# STM32L552 register map
File version: 1.0
CPU: CM33 r0p1, little endian, MPU, FPU, 3 interrupt priority bits
Registers are 32-bit, read-write, reset 0x0 unless marked. A register's access mark holds for its fields unless they carry their own. Offsets are from the block's base; [hi:lo] are bit positions; {n}, {i} and the like mark numbered series.

## GTZC_MPCBB1
Base 0x40032C00
Same registers: GTZC_MPCBB2 0x40033000, SEC_GTZC_MPCBB1 0x50032C00, SEC_GTZC_MPCBB2 0x50033000
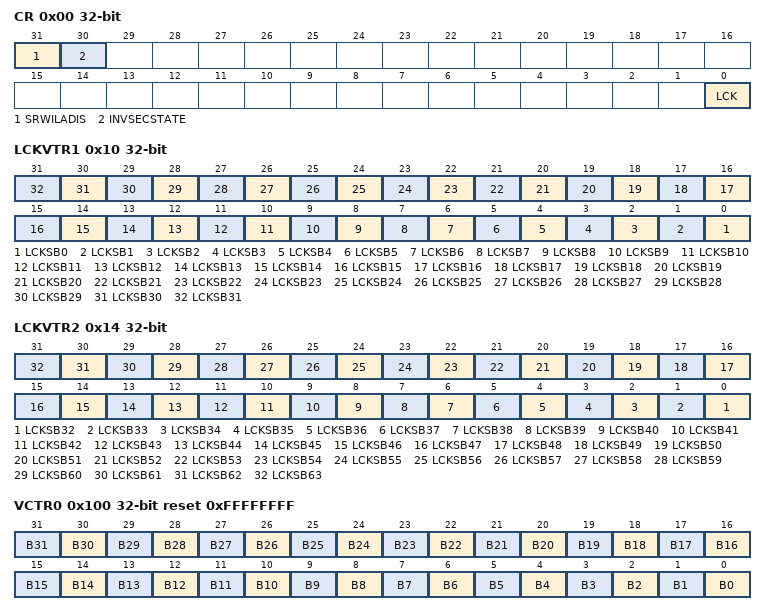
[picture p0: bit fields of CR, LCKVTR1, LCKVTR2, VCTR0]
0x00 CR — MPCBB control register
  [31] SRWILADIS, [30] INVSECSTATE, [0] LCK
0x10 LCKVTR1 — MPCBB control register
  [n] LCKSB{n} (n=0..31)
0x14 LCKVTR2 — MPCBB control register
  [n-32] LCKSB{n} (n=32..63)
0x100 VCTR0 reset 0xFFFFFFFF — MPCBBx vector register
  [n] B{n} (n=0..31)
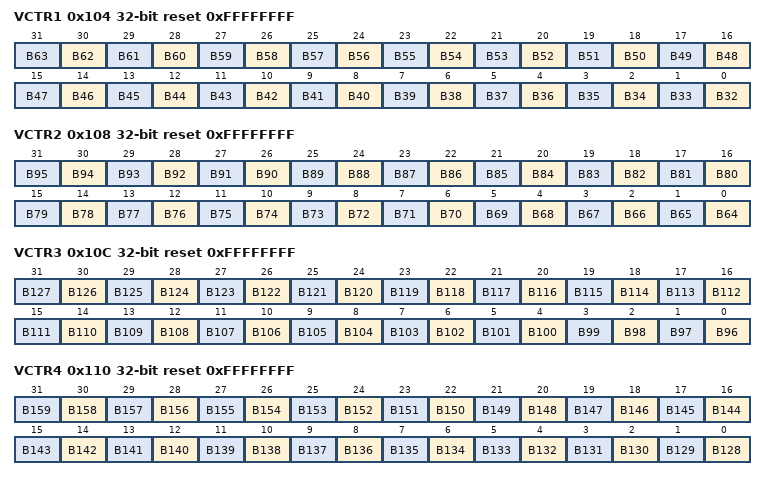
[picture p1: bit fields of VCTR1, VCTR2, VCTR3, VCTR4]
0x104 VCTR1 reset 0xFFFFFFFF — MPCBBx vector register
  [n-32] B{n} (n=32..63)
0x108 VCTR2 reset 0xFFFFFFFF — MPCBBx vector register
  [n-64] B{n} (n=64..95)
0x10C VCTR3 reset 0xFFFFFFFF — MPCBBx vector register
  [n-96] B{n} (n=96..127)
0x110 VCTR4 reset 0xFFFFFFFF — MPCBBx vector register
  [n-128] B{n} (n=128..159)
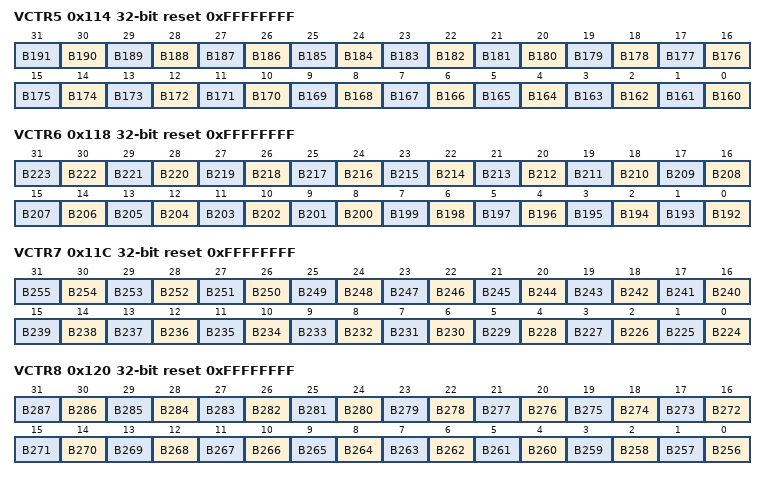
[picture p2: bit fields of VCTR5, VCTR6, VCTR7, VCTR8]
0x114 VCTR5 reset 0xFFFFFFFF — MPCBBx vector register
  [n-160] B{n} (n=160..191)
0x118 VCTR6 reset 0xFFFFFFFF — MPCBBx vector register
  [n-192] B{n} (n=192..223)
0x11C VCTR7 reset 0xFFFFFFFF — MPCBBx vector register
  [n-224] B{n} (n=224..255)
0x120 VCTR8 reset 0xFFFFFFFF — MPCBBx vector register
  [n-256] B{n} (n=256..287)
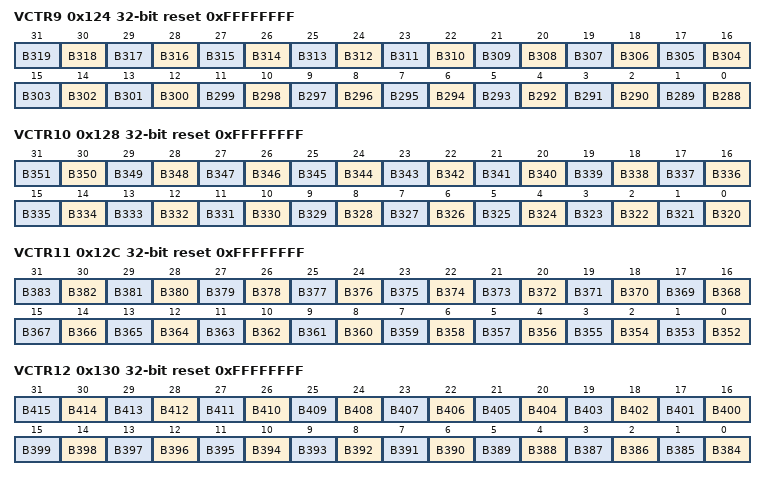
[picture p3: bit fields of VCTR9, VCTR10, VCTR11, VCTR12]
0x124 VCTR9 reset 0xFFFFFFFF — MPCBBx vector register
  [n-288] B{n} (n=288..319)
0x128 VCTR10 reset 0xFFFFFFFF — MPCBBx vector register
  [n-320] B{n} (n=320..351)
0x12C VCTR11 reset 0xFFFFFFFF — MPCBBx vector register
  [n-352] B{n} (n=352..383)
0x130 VCTR12 reset 0xFFFFFFFF — MPCBBx vector register
  [n-384] B{n} (n=384..415)
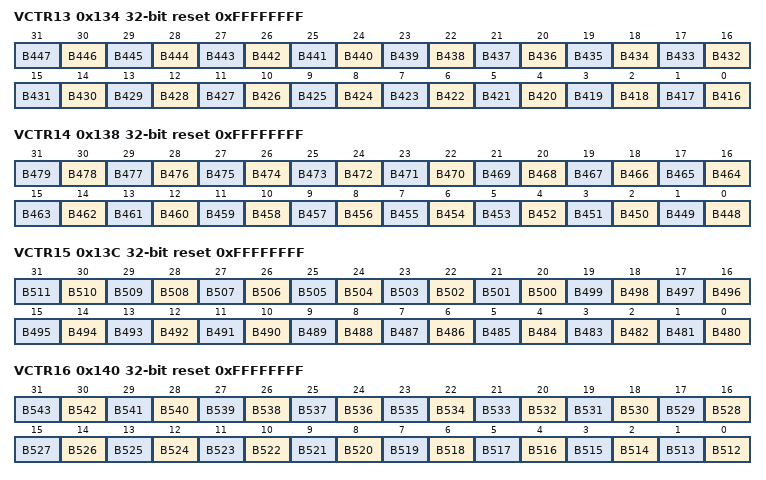
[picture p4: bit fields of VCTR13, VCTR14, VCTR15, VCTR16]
0x134 VCTR13 reset 0xFFFFFFFF — MPCBBx vector register
  [n-416] B{n} (n=416..447)
0x138 VCTR14 reset 0xFFFFFFFF — MPCBBx vector register
  [n-448] B{n} (n=448..479)
0x13C VCTR15 reset 0xFFFFFFFF — MPCBBx vector register
  [n-480] B{n} (n=480..511)
0x140 VCTR16 reset 0xFFFFFFFF — MPCBBx vector register
  [n-512] B{n} (n=512..543)
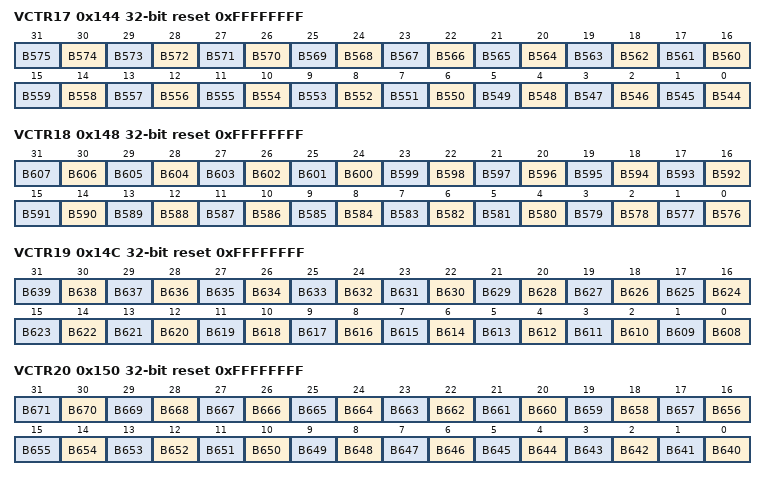
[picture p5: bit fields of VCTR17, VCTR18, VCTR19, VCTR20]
0x144 VCTR17 reset 0xFFFFFFFF — MPCBBx vector register
  [n-544] B{n} (n=544..575)
0x148 VCTR18 reset 0xFFFFFFFF — MPCBBx vector register
  [n-576] B{n} (n=576..607)
0x14C VCTR19 reset 0xFFFFFFFF — MPCBBx vector register
  [n-608] B{n} (n=608..639)
0x150 VCTR20 reset 0xFFFFFFFF — MPCBBx vector register
  [n-640] B{n} (n=640..671)
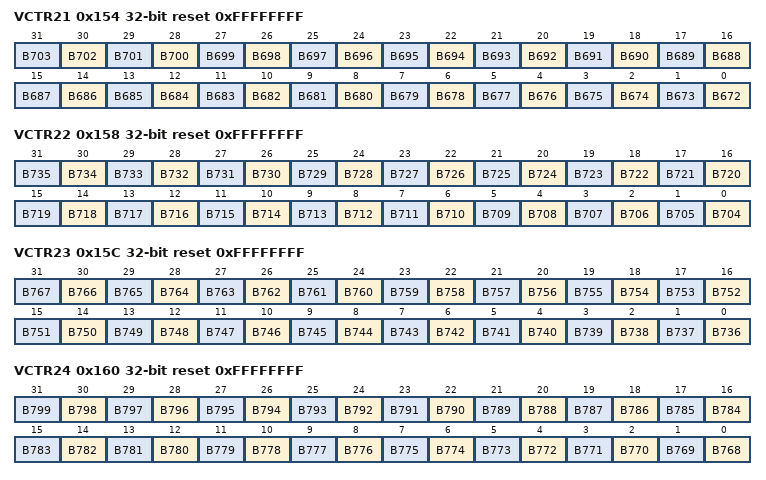
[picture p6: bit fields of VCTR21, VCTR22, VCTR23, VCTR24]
0x154 VCTR21 reset 0xFFFFFFFF — MPCBBx vector register
  [n-672] B{n} (n=672..703)
0x158 VCTR22 reset 0xFFFFFFFF — MPCBBx vector register
  [n-704] B{n} (n=704..735)
0x15C VCTR23 reset 0xFFFFFFFF — MPCBBx vector register
  [n-736] B{n} (n=736..767)
0x160 VCTR24 reset 0xFFFFFFFF — MPCBBx vector register
  [n-768] B{n} (n=768..799)
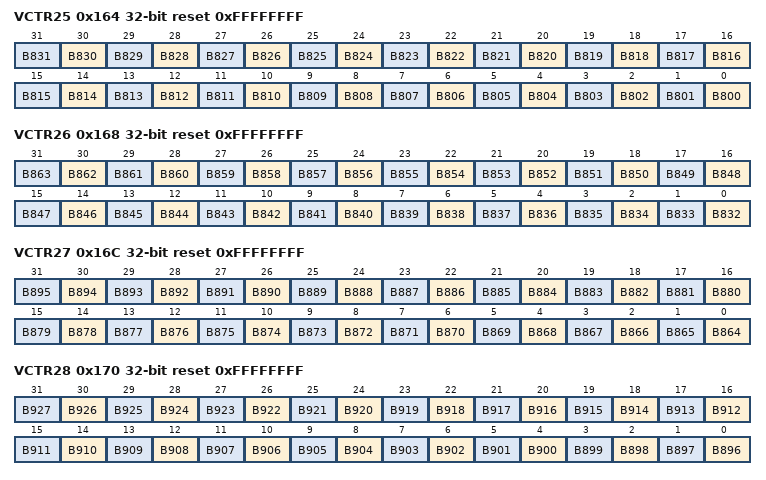
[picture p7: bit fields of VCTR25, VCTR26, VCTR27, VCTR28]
0x164 VCTR25 reset 0xFFFFFFFF — MPCBBx vector register
  [n-800] B{n} (n=800..831)
0x168 VCTR26 reset 0xFFFFFFFF — MPCBBx vector register
  [n-832] B{n} (n=832..863)
0x16C VCTR27 reset 0xFFFFFFFF — MPCBBx vector register
  [n-864] B{n} (n=864..895)
0x170 VCTR28 reset 0xFFFFFFFF — MPCBBx vector register
  [n-896] B{n} (n=896..927)
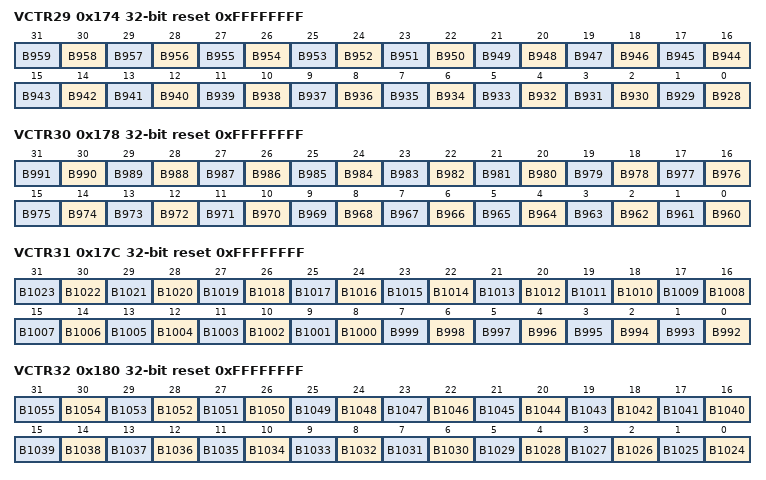
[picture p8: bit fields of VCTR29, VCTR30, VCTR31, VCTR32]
0x174 VCTR29 reset 0xFFFFFFFF — MPCBBx vector register
  [n-928] B{n} (n=928..959)
0x178 VCTR30 reset 0xFFFFFFFF — MPCBBx vector register
  [n-960] B{n} (n=960..991)
0x17C VCTR31 reset 0xFFFFFFFF — MPCBBx vector register
  [n-992] B{n} (n=992..1023)
0x180 VCTR32 reset 0xFFFFFFFF — MPCBBx vector register
  [n-1024] B{n} (n=1024..1055)
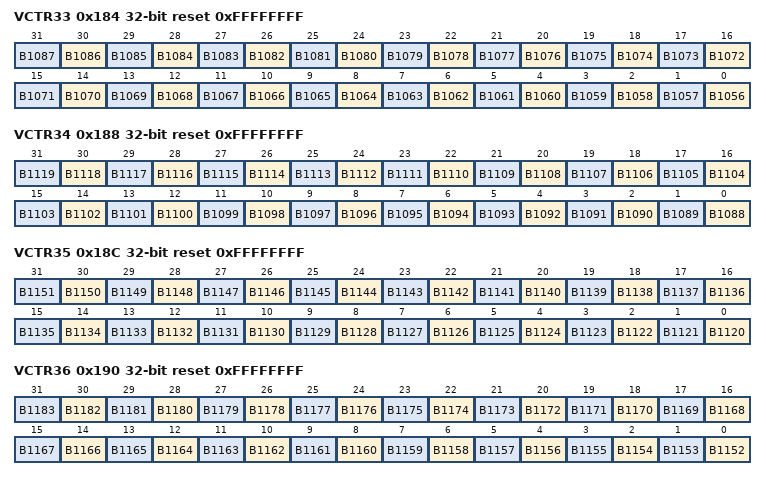
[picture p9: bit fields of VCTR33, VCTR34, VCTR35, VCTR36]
0x184 VCTR33 reset 0xFFFFFFFF — MPCBBx vector register
  [n-1056] B{n} (n=1056..1087)
0x188 VCTR34 reset 0xFFFFFFFF — MPCBBx vector register
  [n-1088] B{n} (n=1088..1119)
0x18C VCTR35 reset 0xFFFFFFFF — MPCBBx vector register
  [n-1120] B{n} (n=1120..1151)
0x190 VCTR36 reset 0xFFFFFFFF — MPCBBx vector register
  [n-1152] B{n} (n=1152..1183)
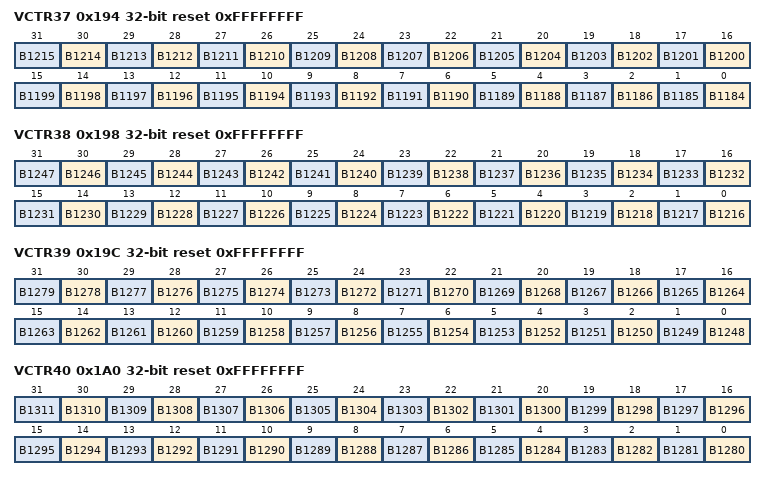
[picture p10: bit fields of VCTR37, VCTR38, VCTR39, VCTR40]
0x194 VCTR37 reset 0xFFFFFFFF — MPCBBx vector register
  [n-1184] B{n} (n=1184..1215)
0x198 VCTR38 reset 0xFFFFFFFF — MPCBBx vector register
  [n-1216] B{n} (n=1216..1247)
0x19C VCTR39 reset 0xFFFFFFFF — MPCBBx vector register
  [n-1248] B{n} (n=1248..1279)
0x1A0 VCTR40 reset 0xFFFFFFFF — MPCBBx vector register
  [n-1280] B{n} (n=1280..1311)
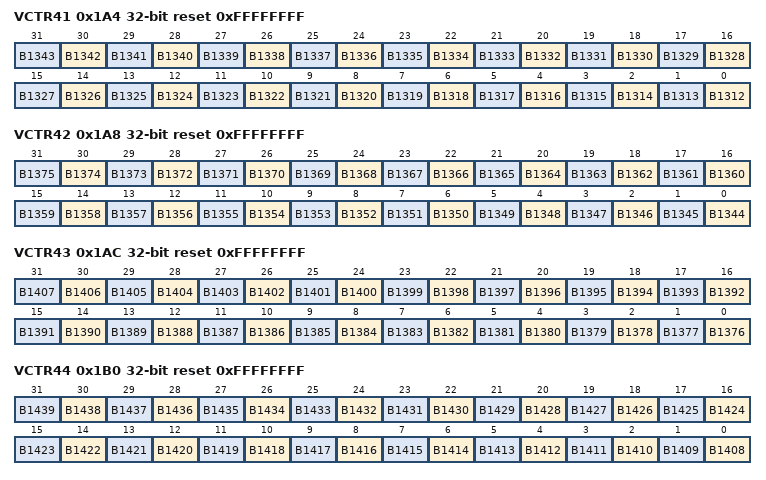
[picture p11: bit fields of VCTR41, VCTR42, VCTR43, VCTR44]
0x1A4 VCTR41 reset 0xFFFFFFFF — MPCBBx vector register
  [n-1312] B{n} (n=1312..1343)
0x1A8 VCTR42 reset 0xFFFFFFFF — MPCBBx vector register
  [n-1344] B{n} (n=1344..1375)
0x1AC VCTR43 reset 0xFFFFFFFF — MPCBBx vector register
  [n-1376] B{n} (n=1376..1407)
0x1B0 VCTR44 reset 0xFFFFFFFF — MPCBBx vector register
  [n-1408] B{n} (n=1408..1439)
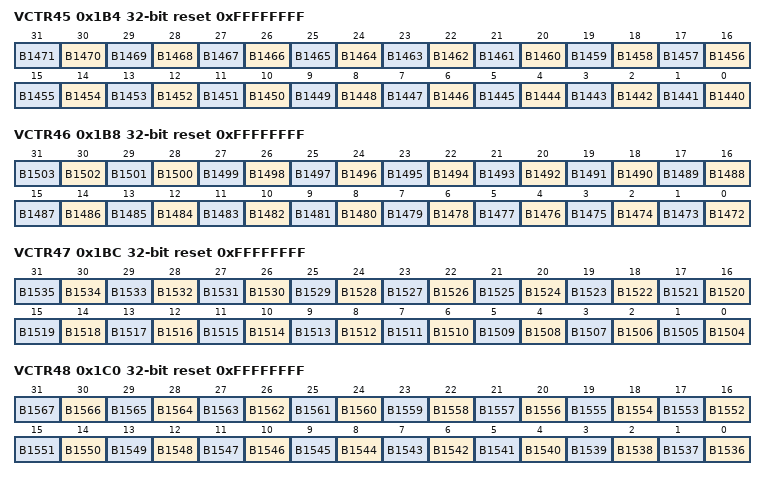
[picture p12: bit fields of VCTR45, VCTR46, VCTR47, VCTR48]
0x1B4 VCTR45 reset 0xFFFFFFFF — MPCBBx vector register
  [n-1440] B{n} (n=1440..1471)
0x1B8 VCTR46 reset 0xFFFFFFFF — MPCBBx vector register
  [n-1472] B{n} (n=1472..1503)
0x1BC VCTR47 reset 0xFFFFFFFF — MPCBBx vector register
  [n-1504] B{n} (n=1504..1535)
0x1C0 VCTR48 reset 0xFFFFFFFF — MPCBBx vector register
  [n-1536] B{n} (n=1536..1567)
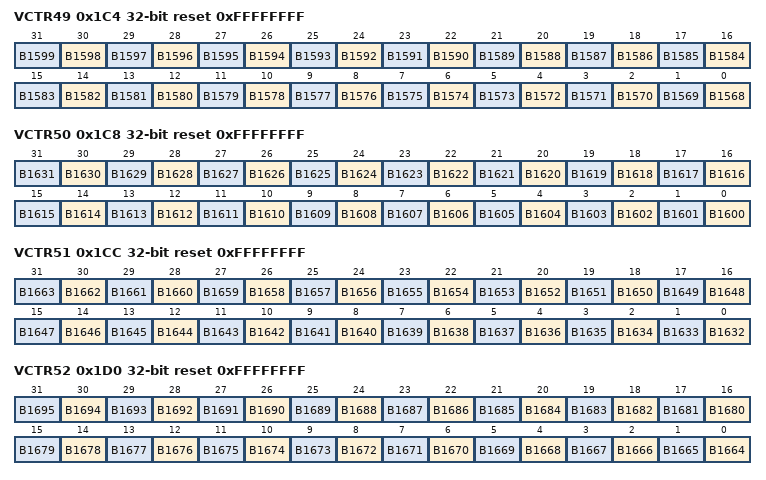
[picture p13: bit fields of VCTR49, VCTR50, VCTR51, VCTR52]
0x1C4 VCTR49 reset 0xFFFFFFFF — MPCBBx vector register
  [n-1568] B{n} (n=1568..1599)
0x1C8 VCTR50 reset 0xFFFFFFFF — MPCBBx vector register
  [n-1600] B{n} (n=1600..1631)
0x1CC VCTR51 reset 0xFFFFFFFF — MPCBBx vector register
  [n-1632] B{n} (n=1632..1663)
0x1D0 VCTR52 reset 0xFFFFFFFF — MPCBBx vector register
  [n-1664] B{n} (n=1664..1695)
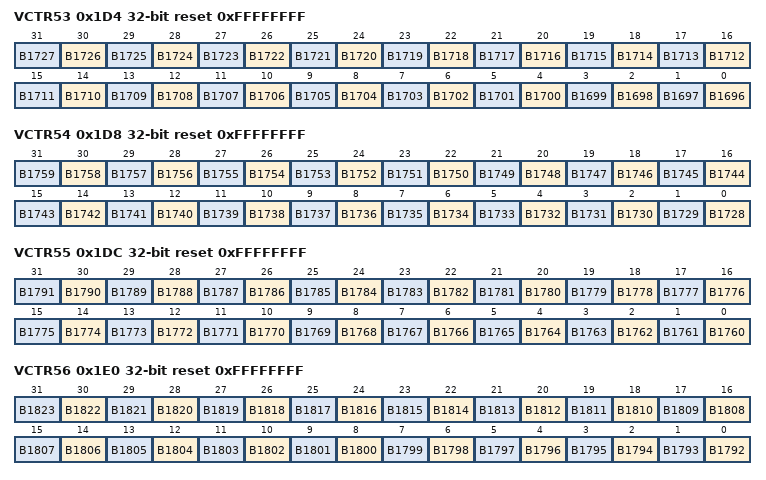
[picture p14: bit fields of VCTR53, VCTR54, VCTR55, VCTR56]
0x1D4 VCTR53 reset 0xFFFFFFFF — MPCBBx vector register
  [n-1696] B{n} (n=1696..1727)
0x1D8 VCTR54 reset 0xFFFFFFFF — MPCBBx vector register
  [n-1728] B{n} (n=1728..1759)
0x1DC VCTR55 reset 0xFFFFFFFF — MPCBBx vector register
  [n-1760] B{n} (n=1760..1791)
0x1E0 VCTR56 reset 0xFFFFFFFF — MPCBBx vector register
  [n-1792] B{n} (n=1792..1823)
0x1E4 VCTR57 reset 0xFFFFFFFF — MPCBBx vector register
  [n-1824] B{n} (n=1824..1855)
0x1E8 VCTR58 reset 0xFFFFFFFF — MPCBBx vector register
  [n-1856] B{n} (n=1856..1887)
0x1EC VCTR59 reset 0xFFFFFFFF — MPCBBx vector register
  [n-1888] B{n} (n=1888..1919)
0x1F0 VCTR60 reset 0xFFFFFFFF — MPCBBx vector register
  [n-1920] B{n} (n=1920..1951)
0x1F4 VCTR61 reset 0xFFFFFFFF — MPCBBx vector register
  [n-1952] B{n} (n=1952..1983)
0x1F8 VCTR62 reset 0xFFFFFFFF — MPCBBx vector register
  [n-1984] B{n} (n=1984..2015)
0x1FC VCTR63 reset 0xFFFFFFFF — MPCBBx vector register
  [n-2016] B{n} (n=2016..2047)
